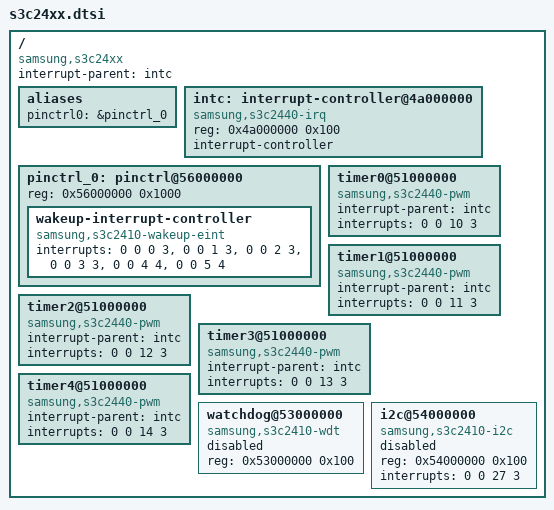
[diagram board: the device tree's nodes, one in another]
// SPDX-License-Identifier: GPL-2.0
/*
 * Samsung's S3C24XX family device tree source
 *
 * Copyright (c) 2013 Heiko Stuebner <heiko@sntech.de>
 */

/ {
	compatible = "samsung,s3c24xx";
	interrupt-parent = <&intc>;
	#address-cells = <1>;
	#size-cells = <1>;

	aliases {
		pinctrl0 = &pinctrl_0;
		//serial0 = &uart0;
		//serial1 = &uart1;
		//serial2 = &uart2;
	};

	intc:interrupt-controller@4a000000 {
		compatible = "samsung,s3c2440-irq";
		reg = <0x4a000000 0x100>;
		interrupt-controller;
		#interrupt-cells = <4>;
	};

	pinctrl_0: pinctrl@56000000 {
		reg = <0x56000000 0x1000>;

		wakeup-interrupt-controller {
			compatible = "samsung,s3c2410-wakeup-eint";
			interrupts = <0 0 0 3>,
				     <0 0 1 3>,
				     <0 0 2 3>,
				     <0 0 3 3>,
				     <0 0 4 4>,
				     <0 0 5 4>;
		};
	};

	timer0@51000000 {
		compatible = "samsung,s3c2440-pwm";
		interrupt-parent = <&intc>;
		interrupts = <0 0 10 3>;
		#pwm-cells = <4>;
	};

	timer1@51000000 {
		compatible = "samsung,s3c2440-pwm";
		interrupt-parent = <&intc>;
		interrupts = <0 0 11 3>;
		#pwm-cells = <4>;
	};

	timer2@51000000 {
		compatible = "samsung,s3c2440-pwm";
		interrupt-parent = <&intc>;
		interrupts = <0 0 12 3>;
		#pwm-cells = <4>;
	};

	timer3@51000000 {
		compatible = "samsung,s3c2440-pwm";
		interrupt-parent = <&intc>;
		interrupts = <0 0 13 3>;
		#pwm-cells = <4>;
	};
	timer4@51000000 {
		compatible = "samsung,s3c2440-pwm";
		interrupt-parent = <&intc>;
		interrupts = <0 0 14 3>;
		#pwm-cells = <4>;
	};

	watchdog@53000000 {
		compatible = "samsung,s3c2410-wdt";
		reg = <0x53000000 0x100>;
		status = "disabled";
	};

	/*rtc@57000000 {
		compatible = "samsung,s3c2410-rtc";
		reg = <0x57000000 0x100>;
		interrupts = <0 0 30 3>, <0 0 8 3>;
		status = "disabled";
	};
*/
	i2c@54000000 {
		compatible = "samsung,s3c2410-i2c";
		reg = <0x54000000 0x100>;
		interrupts = <0 0 27 3>;
		#address-cells = <1>;
		#size-cells = <0>;
		status = "disabled";
	};
};
